# RTS591x register map
Vendor: Realtek Semiconductor Corp.; Series: RTS591x Series; File version: 1.0
CPU: ARMV8MML r0p0, little endian, MPU, FPU, VTOR, 3 interrupt priority bits, 4 SAU regions
Registers are 32-bit, read-write, reset 0x0 unless marked. A register's access mark holds for its fields unless they carry their own. Offsets are from the block's base; [hi:lo] are bit positions; {n}, {i} and the like mark numbered series; 'fields as' and 'values as' point back to an identical list.

## SYSTEM — System Controller
Base 0x40020000
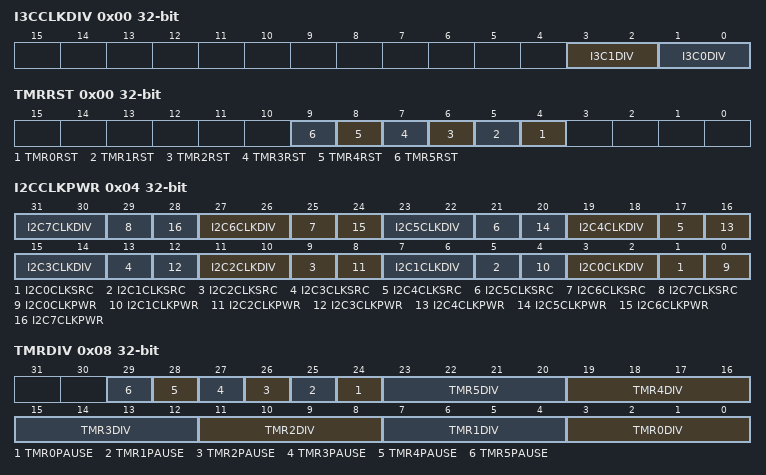
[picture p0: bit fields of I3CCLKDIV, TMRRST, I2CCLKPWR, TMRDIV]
0x00 I3CCLKDIV — I3C CLOCK DIVIDER REGISTER
  [3:2] I3C1DIV — I3C1 Clock Divider
    0=DIV1 (I3C clock is PLL/1); 1=DIV2 (I3C clock is PLL/2); 2=DIV4 (I3C clock is PLL/4); other=NOT_USED (Reserved values. Do not use.)
  [1:0] I3C0DIV — I3C0 Clock Divider
    values as I3C1DIV
0x00 TMRRST (alternate view of I3CCLKDIV) — TIMER RESET REGISTER
  [all] fields
    0=RESET (Hold Timer in reset stage); 1=ACTIVE (Timer is in active stage)
  [n+4] TMR{n}RST (n=0..5) — Reset Timer{n}, low-active
0x04 I2CCLKPWR — I2C CLOCK POWER REGISTER
  [4n+3:4n+2] I2C{n}CLKDIV (n=0..7) — I2C{n} Clock Divider
    0=DIV1 (I2C clock is source/1); 1=DIV2 (I2C clock is source/2); 2=DIV4 (I2C clock is source/4); 3=DIV8 (I2C clock is source/8)
  [4n+1] I2C{n}CLKSRC (n=0..7) — I2C{n} Clock Source
    1=RC25M (I2C clock source is from RC25M); 0=PLL (I2C clock source is from PLL)
  [4n] I2C{n}CLKPWR (n=0..7) — I2C{n} Clock Power
    0=DISABLE (Disable I2C clock Power); 1=ENABLE (Enable I2C clock power)
0x08 TMRDIV — TIMER DIVIDER REGISTER
  [n+24] TMR{n}PAUSE (n=0..5) — Timer{n} Clock Pause
    0=ACTIVE (Timer clock is active); 1=PAUSE (Timer clock is pause)
  [4n+3:4n] TMR{n}DIV (n=0..5) — Timer{n} Clock Divider
    0=DIV1 (Timer clock is RC25M/1); 1=DIV2 (Timer clock is RC25M/2); 2=DIV4 (Timer clock is RC25M/4); 3=DIV8 (Timer clock is RC25M/8); 4=DIV16 (Timer clock is RC25M/16); 5=DIV32 (Timer clock is RC25M/32); 6=DIV64 (Timer clock is RC25M/64); 7=DIV128 (Timer clock is RC25M/128); 8=DIV256 (Timer clock is RC25M/256); other=NOT_USED (Reserved values. Do not use.)
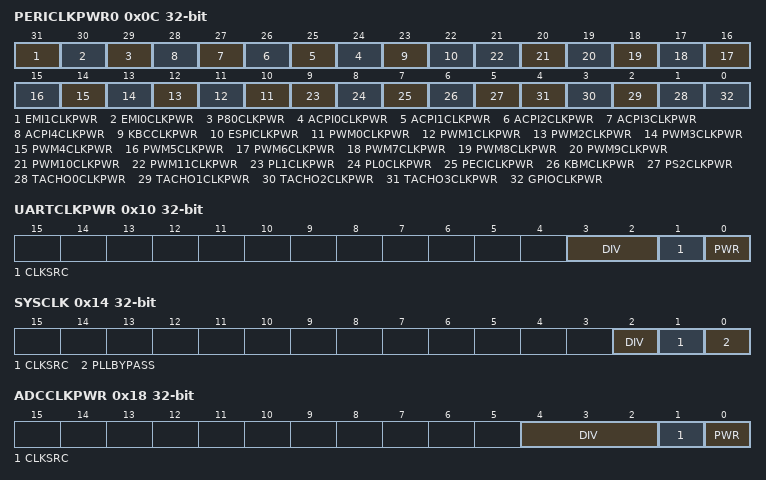
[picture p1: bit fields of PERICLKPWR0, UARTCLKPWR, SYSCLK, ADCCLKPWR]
0x0C PERICLKPWR0 — PERIPHERAL CLOCK POWER REGISTER #0
  [31] EMI1CLKPWR — EMI1 Clock Power
    0=DISABLE (Disable EMI1 Clock Power); 1=ENABLE (Enable EMI1 Clock Power)
  [30] EMI0CLKPWR — EMI0 Clock Power
    0=DISABLE (Disable EMI0 Clock Power); 1=ENABLE (Enable EMI0 Clock Power)
  [29] P80CLKPWR — Port80 Clock Power
    0=DISABLE (Disable Port80 Clock Power); 1=ENABLE (Enable Port80 Clock Power)
  [n+24] ACPI{n}CLKPWR (n=0..4) — ACPI{n} Clock Power
    0=DISABLE (Disable ACPI{n} Clock Power); 1=ENABLE (Enable ACPI{n} Clock Power)
  [23] KBCCLKPWR — KBC Clock Power
    0=DISABLE (Disable KBC Clock Power); 1=ENABLE (Enable KBC Clock Power)
  [22] ESPICLKPWR — eSPI Clock Power
    0=DISABLE (Disable eSPI Clock Power); 1=ENABLE (Enable eSPI Clock Power)
  [n+10] PWM{n}CLKPWR (n=0..11) — PWM{n} Clock Power
    0=DISABLE (Disable PWM{n} Clock Power); 1=ENABLE (Enable PWM{n} Clock Power)
  [9] PL1CLKPWR — PWMLED1 Clock Power
    0=DISABLE (Disable PWMLED1 Clock Power); 1=ENABLE (Enable PWMLED1 Clock Power)
  [8] PL0CLKPWR — PWMLED0 Clock Power
    0=DISABLE (Disable PWMLED0 Clock Power); 1=ENABLE (Enable PWMLED0 Clock Power)
  [7] PECICLKPWR — PECI Clock Power
    0=DISABLE (Disable PECI Clock Power); 1=ENABLE (Enable PECI Clock Power)
  [6] KBMCLKPWR — KBM Clock Power
    0=DISABLE (Disable KBM Clock Power); 1=ENABLE (Enable KBM Clock Power)
  [5] PS2CLKPWR — PS2 Clock Power
    0=DISABLE (Disable PS2 Clock Power); 1=ENABLE (Enable PS2 Clock Power)
  [n+1] TACHO{n}CLKPWR (n=0..3) — Tachometer{n} Clock Power
    0=DISABLE (Disable Tachometer{n} Clock Power); 1=ENABLE (Enable Tachometer{n} Clock Power)
  [0] GPIOCLKPWR — GPIO Clock Power
    0=DISABLE (Disable GPIO Clock Power); 1=ENABLE (Enable GPIO Clock Power)
0x10 UARTCLKPWR — UART CLOCK POWER REGISTER
  [3:2] DIV — UART Clock Divider
    0=UART clock is source/1; 1=UART clock is source/2; 2=UART clock is source/4; 3=UART clock is source/8
  [1] CLKSRC — UART Clock Source
    0=RC25M (UART clock source is from RC25M); 1=PLL (UART clock source is from PLL)
  [0] PWR — UART Clock Power
    0=DISABLE (Disable UART Clock Power); 1=ENABLE (Enable UART Clock Power)
0x14 SYSCLK — SYSTEM CLOCK REGISTER
  [2] DIV — System Clock Divider
    0=System clock is source/1; 1=System clock is source/2
  [1] CLKSRC — System Clock Source
    0=RC25M (System clock source is from RC25M); 1=PLL (System clock source is from PLL)
  [0] PLLBYPASS — Bypass PLL from Analog De-bounce Circuit
    0=NOT_BYPASS (PLL output through de-bounce); 1=BYPASS (PLL output bypass de-bounce)
0x18 ADCCLKPWR — ADC CLOCK POWER REGISTER
  [4:2] DIV — ADC Clock Divider
    {v}=ADC clock is source/{v+1} (v=0..3); 4=ADC clock is source/6; 5=ADC clock is source/8; 6=ADC clock is source/12; 7=ADC clock is source/16
  [1] CLKSRC — ADC Clock Source
    0=RC25M (ADC clock source is from RC25M); 1=PLL (ADC clock source is from PLL)
  [0] PWR — ADC Clock Power
    0=DISABLE (Disable ADC Clock Power); 1=ENABLE (Enable ADC Clock Power)
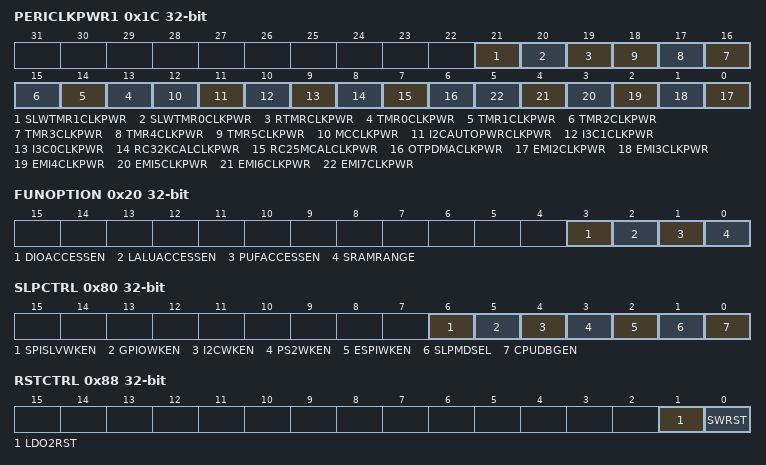
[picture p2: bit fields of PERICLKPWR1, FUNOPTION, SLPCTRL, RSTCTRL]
0x1C PERICLKPWR1 — PERIPHERAL CLOCK POWER REGISTER #1
  [21] SLWTMR1CLKPWR — Slow Timer 1 Clock Power
    0=DISABLE (Disable Slow Timer 1 Clock Power); 1=ENABLE (Enable Slow Timer 1 Clock Power)
  [20] SLWTMR0CLKPWR — Slow Timer 0 Clock Power
    0=DISABLE (Disable Slow Timer 0 Clock Power); 1=ENABLE (Enable Slow Timer 0 Clock Power)
  [19] RTMRCLKPWR — RTOS Timer Clock Power
    0=DISABLE (Disable RTOS Timer Clock Power); 1=ENABLE (Enable RTOS Timer Clock Power)
  [n+13] TMR{n}CLKPWR (n=0..5) — Timer{n} Clock Power
    0=DISABLE (Disable Timer{n} Clock Power); 1=ENABLE (Enable Timer{n} Clock Power)
  [12] MCCLKPWR — Monotonic Counter Clock Power
    0=DISABLE (Disable Monotonic Counter Clock Power); 1=ENABLE (Enable Monotonic Counter Clock Power)
  [11] I2CAUTOPWRCLKPWR — I2C Auto-Power Circuit Clock Power
    0=DISABLE (Disable I2C Auto-Power Circuit Clock Power); 1=ENABLE (Enable I2C Auto-Power Circuit Clock Power)
  [10] I3C1CLKPWR — I3C1 Clock Power
    0=DISABLE (Disable I3C1 Clock Power); 1=ENABLE (Enable I3C1 Clock Power)
  [9] I3C0CLKPWR — I3C0 Clock Power
    0=DISABLE (Disable I3C0 Clock Power); 1=ENABLE (Enable I3C0 Clock Power)
  [8] RC32KCALCLKPWR — RC32K Calibration Circuit Clock Power
    0=DISABLE (Disable RC32K Calibration Circuit Clock Power); 1=ENABLE (Enable RC32K Calibration Circuit Clock Power)
  [7] RC25MCALCLKPWR — RC25M Calibration Circuit Clock Power
    0=DISABLE (Disable RC25M Calibration Circuit Clock Power); 1=ENABLE (Enable RC25M Calibration Circuit Clock Power)
  [6] OTPDMACLKPWR — OTP DMA Clock Power
    0=DISABLE (Disable OTP DMA Clock Power); 1=ENABLE (Enable OTP DMA Clock Power)
  [n-2] EMI{n}CLKPWR (n=2..7) — EMI{n} Clock Power
    0=DISABLE (Disable EMI{n} Clock Power); 1=ENABLE (Enable EMI{n} Clock Power)
0x20 FUNOPTION — FUNCTION OPTIONAL REGISTER
  [3] DIOACCESSEN — Dedicated I/O Accessible Permission
    0=DISABLE (Dedicated I/O is not accessible); 1=ENABLE (Dedicated I/O is accessible)
  [2] LALUACCESSEN — Lalu Engine Accessible Permission
    0=ENABLE (Lalu Engine is accessible); 1=DISABLE (Lalu Engine is not accessible)
  [1] PUFACCESSEN — PUF Accessible Permission
    0=ENABLE (PUF is accessible); 1=DISABLE (PUF is not accessible)
  [0] SRAMRANGE — SRAM Accessible Range
    0=384K (SRAM range is 384K); 1=256K (SRAM range is 256K)
0x24 CPURSTADDR0 — CPU RESET ADDRESS REGISTER #0
0x28 CPURSTADDR1 — CPU RESET ADDRESS REGISTER #1
0x80 SLPCTRL — SYSTEM SLEEP CONTROL REGISTER
  [6] SPISLVWKEN — SPI Slave Wake-up Enable
    0=DISABLE (Disable SPI Slave wake-up); 1=ENABLE (Enable SPI Slave wake-up)
  [5] GPIOWKEN — GPIO Wake-up Enable
    0=DISABLE (Disable GPIO wake-up); 1=ENABLE (Enable GPIO wake-up)
  [4] I2CWKEN — I2C Wake-up Enable
    0=DISABLE (Disable I2C wake-up); 1=ENABLE (Enable I2C wake-up)
  [3] PS2WKEN — PS2 Wake-up Enable
    0=DISABLE (Disable PS2 wake-up); 1=ENABLE (Enable PS2 wake-up)
  [2] ESPIWKEN — eSPI Wake-up Enable
    0=DISABLE (Disable eSPI wake-up); 1=ENABLE (Enable eSPI wake-up)
  [1] SLPMDSEL — Sleep Mode Selection
    0=LIGHT_SLEEP (Using Light-sleep Mode); 1=HEAVRY_SLEEP (Using Heavry-sleep Mode)
  [0] CPUDBGEN — CPU Debug Function Enable
    0=DISABLE (Disable CPU Debug Function); 1=ENABLE (Enable CPU Debug Function)
0x88 RSTCTRL — SYSTEM RESET REGISTER
  [1] LDO2RST write-1-clears — LDO2 Reset
    0=DO_NOTHING; 1=RESET (Reset all of LDO2 domain registers)
  [0] SWRST write-1-clears — Software Reset
    0=DO_NOTHING; 1=RESET (Reset all of control registers)
{0x8C+4i} MSRAMCTRL{i} (i=0..3) — Main SRAM CONTROL REGISTER #{i}
0x9C ESPISRAMCTRL — ESPI SRAM CONTROL REGISTER
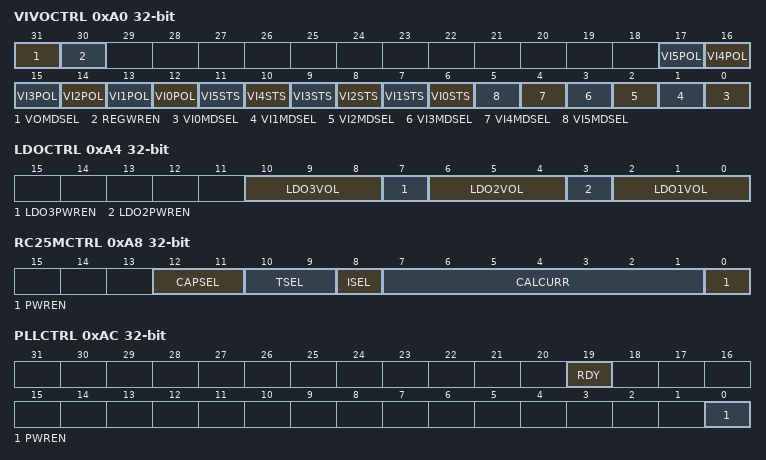
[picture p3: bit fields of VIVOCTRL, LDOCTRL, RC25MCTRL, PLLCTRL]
0xA0 VIVOCTRL — VINVOUT CONTROL REGISTER
  [31] VOMDSEL — VO Mode Selection
    0=VO (Using VO function); 1=GPIO (Using GPIO function)
  [30] REGWREN — Register Write Enable
    0=DISABLE (Disable register write); 1=ENABLE (Enable register write)
  [n+12] VI{n}POL (n=0..5) — VI Polarity
    0=RISING (Rising-edge detection); 1=FALLING (Falling-edge detection)
  [n+6] VI{n}STS ro (n=0..5) — VI{n} Status
    0=NOTHING; 1=DETECTED (VI{n} falling/rising-edge is detected)
  [n] VI{n}MDSEL (n=0..5) — VI{n} Mode Select
    0=VI (Select VI function); 1=GPIO (Select GPIO Function)
0xA4 LDOCTRL — LDO CONTROL REGISTER
  [10:8] LDO3VOL — Select LDO3 Voltage
    0=1V (LDO3 output voltage is 1.0V); 1=0_8V (LDO3 output voltage is 0.8V); 2=0_9V (LDO3 output voltage is 0.9V); 3=1_0V (LDO3 output voltage is 1.0V); 4=1_05V (LDO3 output voltage is 1.05V); 5=1_1V (LDO3 output voltage is 1.1V); other=NOT_USED (Reserved values. Do not use.)
  [7] LDO3PWREN — LDO3 Power Enable
    0=DISALBE (Disable LDO3 power); 1=ENABLE (ENABLE LDO3 power)
  [6:4] LDO2VOL — Select LDO2 Voltage
    0=0_8V (LDO2 output voltage is 0.8V); 1=0_9V (LDO2 output voltage is 0.9V); 2=0_95V (LDO2 output voltage is 0.95V); 3=1_0V (LDO2 output voltage is 1.0V); 4=1_05V (LDO2 output voltage is 1.05V); 5=1_1V (LDO2 output voltage is 1.1V); 6=1_15V (LDO2 output voltage is 1.15V); 7=1_2V (LDO2 output voltage is 1.2V)
  [3] LDO2PWREN — LDO2 Power Enable
    0=DISALBE (Disable LDO2 power); 1=ENABLE (ENABLE LDO2 power)
  [2:0] LDO1VOL — Select LDO1 Voltage
    0=1V (LDO1 output voltage is 1.0V); 1=0_8V (LDO1 output voltage is 0.8V); 2=0_9V (LDO1 output voltage is 0.9V); 3=1_0V (LDO1 output voltage is 1.0V); 4=1_05V (LDO1 output voltage is 1.05V); 5=1_1V (LDO1 output voltage is 1.1V); 6=1_15V (LDO1 output voltage is 1.15V); 7=1_2V (LDO1 output voltage is 1.2V)
0xA8 RC25MCTRL — RC25M ANALOG CONTROL REGISTER
  [12:11] CAPSEL — RC25M Capacitor Selection
  [10:9] TSEL — RC25M Temperature Selection
  [8] ISEL — RC25M Current Selection
  [7:1] CALCURR — RC25M Calibration Current
  [0] PWREN — RC25M Power Enable
    0=DISALBE (Disable RC25M power); 1=ENABLE (ENABLE RC25M power)
0xAC PLLCTRL — PLL ANALOG CONTROL REGISTER
  [19] RDY — PLL Ready and Stable
    0=NOT_READY (PLL is not ready and stable); 1=READY (PLL is ready and stable)
  [0] PWREN — PLL Power Enable
    0=DISALBE (Disable PLL power); 1=ENABLE (ENABLE PLL power)
0xB0 POR1CTRL — POR1 CONTROL REGISTER
0xB4 CRYPTOSRAMCTRL — CRYPTO SRAM CONTROL REGISTER
0xB8 ADCLDOCTRL — ADC LDO CONTROL REGISTER
0xBC ADCANACTRL — ADC ANALOG CONTROL REGISTER
0xC0 ROMBISTCTRL — ROM BIST CONTROL REGISTER
0xC4 BTRMBISTRES0 — BOOTROM BIST RESULT REGISTER #0
0xC8 BTRMBISTRES1 — BOOTROM BIST RESULT REGISTER #1
0xCC LALURMBISTRES0 — LALU ROM BIST RESULT REGISTER #0
0xD0 LALURMBISTRES1 — LALU ROM BIST RESULT REGISTER #1
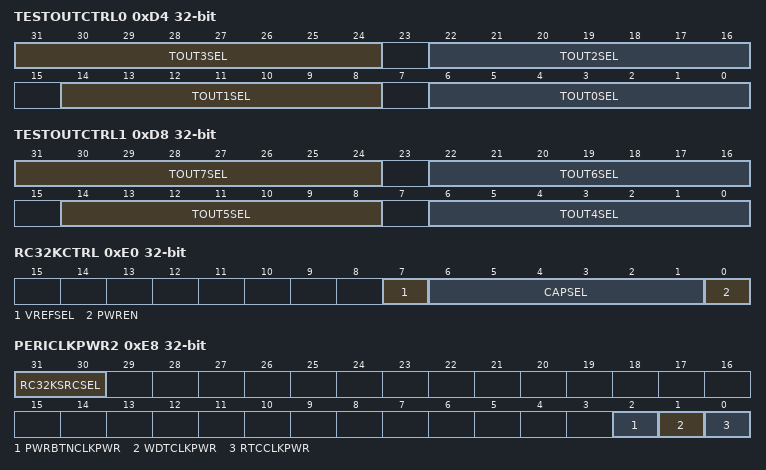
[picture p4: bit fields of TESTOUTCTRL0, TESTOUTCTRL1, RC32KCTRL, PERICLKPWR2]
0xD4 TESTOUTCTRL0 — TESTOUT CONTROL REGISTER #0
  [31:24] TOUT3SEL — TESTOUT3 function selection
  [22:16] TOUT2SEL — TESTOUT2 function selection
  [14:8] TOUT1SEL — TESTOUT1 function selection
  [6:0] TOUT0SEL — TESTOUT0 function selection
0xD8 TESTOUTCTRL1 — TESTOUT CONTROL REGISTER #1
  [31:24] TOUT7SEL — TESTOUT7 function selection
  [22:16] TOUT6SEL — TESTOUT6 function selection
  [14:8] TOUT5SEL — TESTOUT5 function selection
  [6:0] TOUT4SEL — TESTOUT4 function selection
0xE0 RC32KCTRL — RC32K ANALOG CONTROL REGISTER
  [7] VREFSEL — RC32K VREF Selection
  [6:1] CAPSEL — RC32K Capacitor Selection
  [0] PWREN — RC32K Power Enable
    0=DISALBE (Disable RC32K power); 1=ENABLE (Enable RC32K power)
0xE4 POR2CTRL — POR2 CONTROL REGISTER
0xE8 PERICLKPWR2 — PERIPHERAL CLOCK POWER REGISTER #2
  [31:30] RC32KSRCSEL — RC32K Clock Source Selection
    0=RC32M (32K clock is from internal RC32K); 1=RC25M_DIV_750 (32K clock is from internal RC25M/750); 2=GPIO127 (32K clock is from internal RC25M/750); other=NOT_USED (Reserved values. Do not use.)
  [2] PWRBTNCLKPWR — Power Button over WDT Clock Power
    0=DISABLE (Disable Power Button over WDT Clock Power); 1=ENABLE (Enable Power Button over WDT Clock Power)
  [1] WDTCLKPWR — WDT Clock Power
    0=DISABLE (Disable WDT Clock Power); 1=ENABLE (Enable WDT Clock Power)
  [0] RTCCLKPWR — RTC Clock Power
    0=DISABLE (Disable RTC Clock Power); 1=ENABLE (Enable RTC Clock Power)
0xEC BATSRAMCTRL — BATTERY SRAM CONTROL REGISTER
